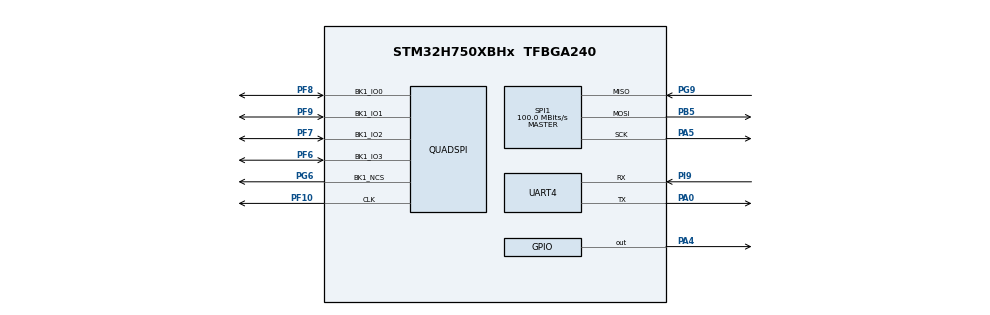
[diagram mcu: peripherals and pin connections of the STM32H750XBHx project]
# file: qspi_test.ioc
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CORTEX_M7.AccessPermission-Cortex_Memory_Protection_Unit_Region0_Settings=MPU_REGION_FULL_ACCESS
CORTEX_M7.BaseAddress-Cortex_Memory_Protection_Unit_Region0_Settings=0x38000000
CORTEX_M7.CPU_DCache=Enabled
CORTEX_M7.CPU_ICache=Enabled
CORTEX_M7.Enable-Cortex_Memory_Protection_Unit_Region0_Settings=MPU_REGION_ENABLE
CORTEX_M7.IsShareable-Cortex_Memory_Protection_Unit_Region0_Settings=MPU_ACCESS_SHAREABLE
CORTEX_M7.MPU_Control=MPU_PRIVILEGED_DEFAULT
CORTEX_M7.Size-Cortex_Memory_Protection_Unit_Region0_Settings=MPU_REGION_SIZE_64KB
CORTEX_M7.default_mode_Activation=0
Dma.Request0=UART4_RX
Dma.UART4_RX.0.Direction=DMA_PERIPH_TO_MEMORY
Dma.UART4_RX.0.EventEnable=DISABLE
Dma.UART4_RX.0.FIFOMode=DMA_FIFOMODE_DISABLE
Dma.UART4_RX.0.Instance=DMA1_Stream0
Dma.UART4_RX.0.MemDataAlignment=DMA_MDATAALIGN_BYTE
Dma.UART4_RX.0.MemInc=DMA_MINC_ENABLE
Dma.UART4_RX.0.Mode=DMA_CIRCULAR
Dma.UART4_RX.0.PeriphDataAlignment=DMA_PDATAALIGN_BYTE
Dma.UART4_RX.0.PeriphInc=DMA_PINC_DISABLE
Dma.UART4_RX.0.Polarity=HAL_DMAMUX_REQ_GEN_RISING
Dma.UART4_RX.0.Priority=DMA_PRIORITY_LOW
Dma.UART4_RX.0.RequestNumber=1
Dma.UART4_RX.0.SignalID=NONE
Dma.UART4_RX.0.SyncEnable=DISABLE
Dma.UART4_RX.0.SyncPolarity=HAL_DMAMUX_SYNC_NO_EVENT
Dma.UART4_RX.0.SyncRequestNumber=1
Dma.UART4_RX.0.SyncSignalID=NONE
Mcu.Family=STM32H7
Mcu.Name=STM32H750XBHx
Mcu.Package=TFBGA240
NVIC.DMA1_Stream0_IRQn=true\:0\:0\:false\:false\:true\:false\:true\:true
NVIC.PriorityGroup=NVIC_PRIORITYGROUP_4
NVIC.QUADSPI_IRQn=true\:0\:0\:false\:false\:true\:true\:true\:true
PA0.Mode=Asynchronous
PA0.Signal=UART4_TX
PA4.GPIO_Speed=GPIO_SPEED_FREQ_VERY_HIGH
PA4.PinState=GPIO_PIN_SET
PA4.Signal=GPIO_Output
PA5.GPIO_Speed=GPIO_SPEED_FREQ_VERY_HIGH
PA5.Mode=Full_Duplex_Master
PA5.Signal=SPI1_SCK
PB5.GPIO_Speed=GPIO_SPEED_FREQ_VERY_HIGH
PB5.Mode=Full_Duplex_Master
PB5.Signal=SPI1_MOSI
PF10.GPIO_Speed=GPIO_SPEED_FREQ_VERY_HIGH
PF10.Mode=Single Bank 1
PF10.Signal=QUADSPI_CLK
PF6.GPIO_Speed=GPIO_SPEED_FREQ_VERY_HIGH
PF6.Mode=Single Bank 1
PF6.Signal=QUADSPI_BK1_IO3
PF7.GPIO_Speed=GPIO_SPEED_FREQ_VERY_HIGH
PF7.Mode=Single Bank 1
PF7.Signal=QUADSPI_BK1_IO2
PF8.GPIO_Speed=GPIO_SPEED_FREQ_VERY_HIGH
PF8.Mode=Single Bank 1
PF8.Signal=QUADSPI_BK1_IO0
PF9.GPIO_Speed=GPIO_SPEED_FREQ_VERY_HIGH
PF9.Mode=Single Bank 1
PF9.Signal=QUADSPI_BK1_IO1
PG6.GPIO_Speed=GPIO_SPEED_FREQ_VERY_HIGH
PG6.Mode=Single Bank 1
PG6.Signal=QUADSPI_BK1_NCS
PG9.GPIO_Speed=GPIO_SPEED_FREQ_VERY_HIGH
PG9.Mode=Full_Duplex_Master
PG9.Signal=SPI1_MISO
PH0-OSC_IN\ (PH0).Mode=HSE-External-Oscillator
PH0-OSC_IN\ (PH0).Signal=RCC_OSC_IN
PH1-OSC_OUT\ (PH1).Mode=HSE-External-Oscillator
PH1-OSC_OUT\ (PH1).Signal=RCC_OSC_OUT
PI9.Mode=Asynchronous
PI9.Signal=UART4_RX
ProjectManager.HeapSize=0x200
ProjectManager.StackSize=0x400
ProjectManager.TargetToolchain=STM32CubeIDE
QUADSPI.ChipSelectHighTime=QSPI_CS_HIGH_TIME_6_CYCLE
QUADSPI.ClockPrescaler=2 - 1
QUADSPI.FifoThreshold=4
QUADSPI.FlashSize=24 - 1
QUADSPI.SampleShifting=QSPI_SAMPLE_SHIFTING_NONE
RCC.ADCFreq_Value=200000000
RCC.APB1Freq_Value=100000000
RCC.APB2Freq_Value=100000000
RCC.APB3Freq_Value=100000000
RCC.APB4Freq_Value=100000000
RCC.CortexFreq_Value=400000000
RCC.D1PPRE=RCC_APB3_DIV2
RCC.D2PPRE1=RCC_APB1_DIV2
RCC.D2PPRE2=RCC_APB2_DIV2
RCC.D3PPRE=RCC_APB4_DIV2
RCC.DIVM1=2
RCC.DIVM2=2
RCC.DIVN1=64
RCC.DIVN2=64
RCC.DIVP2=4
RCC.HCLKFreq_Value=200000000
RCC.HPRE=RCC_HCLK_DIV2
RCC.PLLSourceVirtual=RCC_PLLSOURCE_HSE
RCC.SPI123CLockSelection=RCC_SPI123CLKSOURCE_PLL2
RCC.SYSCLKFreq_VALUE=400000000
RCC.SYSCLKSource=RCC_SYSCLKSOURCE_PLLCLK
RCC.USBFreq_Value=400000000
SPI1.BaudRatePrescaler=SPI_BAUDRATEPRESCALER_2
SPI1.CalculateBaudRate=100.0 MBits/s
SPI1.DataSize=SPI_DATASIZE_8BIT
SPI1.Direction=SPI_DIRECTION_2LINES
SPI1.Mode=SPI_MODE_MASTER
SPI1.VirtualType=VM_MASTER
board=custom

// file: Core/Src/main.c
/* USER CODE BEGIN Header */
/**
  ******************************************************************************
  * @file           : main.c
  * @brief          : Main program body
  ******************************************************************************
  * @attention
  *
  * Copyright (c) 2023 STMicroelectronics.
  * All rights reserved.
  *
  * This software is licensed under terms that can be found in the LICENSE file
  * in the root directory of this software component.
  * If no LICENSE file comes with this software, it is provided AS-IS.
  *
  ******************************************************************************
  */
/* USER CODE END Header */
#include "main.h"
#include "dma.h"
#include "quadspi.h"
#include "spi.h"
#include "usart.h"
#include "gpio.h"

/* USER CODE BEGIN Includes */
#include "qspi_test.h"
/* USER CODE END Includes */

void SystemClock_Config(void);
static void MPU_Config(void);

/* USER CODE BEGIN 0 */

extern DMA_HandleTypeDef hdma_uart4_rx;

static uint8_t spi_id = 0x9F;
static uint8_t spi_id_ret[3] = {0, };

QSPI_CommandTypeDef      s_command;
QSPI_CommandTypeDef      erase_chip;

static __attribute__((section(".none_cache"))) uint8_t uart_rx[100] = {0, };

/* USER CODE END 0 */

int main(void)
{

  /* MPU Configuration--------------------------------------------------------*/
  MPU_Config();

  /* Enable I-Cache---------------------------------------------------------*/
  SCB_EnableICache();

  /* Enable D-Cache---------------------------------------------------------*/
  SCB_EnableDCache();

  /* MCU Configuration--------------------------------------------------------*/

  /* Reset of all peripherals, Initializes the Flash interface and the Systick. */
  HAL_Init();

  /* Configure the system clock */
  SystemClock_Config();

  /* Initialize all configured peripherals */
  MX_GPIO_Init();
  MX_DMA_Init();
  MX_SPI1_Init();
  MX_UART4_Init();
  MX_QUADSPI_Init();
  /* USER CODE BEGIN 2 */
  // mpu region
  HAL_GPIO_WritePin(GPIOA, GPIO_PIN_4, GPIO_PIN_RESET);
  HAL_SPI_Transmit(&hspi1, &spi_id, 1, 0xFF);
  HAL_SPI_Receive(&hspi1, spi_id_ret, 3, 0xFF);
  HAL_GPIO_WritePin(GPIOA, GPIO_PIN_4, GPIO_PIN_SET);

  HAL_UART_Receive_DMA(&huart4, uart_rx, 100);

  qspiTestStart();
  /* USER CODE END 2 */

  /* Infinite loop */
  while (1)
  {

  }
}

void SystemClock_Config(void)
{
  RCC_OscInitTypeDef RCC_OscInitStruct = {0};
  RCC_ClkInitTypeDef RCC_ClkInitStruct = {0};

  /** Supply configuration update enable
  */
  HAL_PWREx_ConfigSupply(PWR_LDO_SUPPLY);

  /** Configure the main internal regulator output voltage
  */
  __HAL_PWR_VOLTAGESCALING_CONFIG(PWR_REGULATOR_VOLTAGE_SCALE1);

  while(!__HAL_PWR_GET_FLAG(PWR_FLAG_VOSRDY)) {}

  /** Macro to configure the PLL clock source
  */
  __HAL_RCC_PLL_PLLSOURCE_CONFIG(RCC_PLLSOURCE_HSE);

  /** Initializes the RCC Oscillators according to the specified parameters
  * in the RCC_OscInitTypeDef structure.
  */
  RCC_OscInitStruct.OscillatorType = RCC_OSCILLATORTYPE_HSE;
  RCC_OscInitStruct.HSEState = RCC_HSE_ON;
  RCC_OscInitStruct.PLL.PLLState = RCC_PLL_ON;
  RCC_OscInitStruct.PLL.PLLSource = RCC_PLLSOURCE_HSE;
  RCC_OscInitStruct.PLL.PLLM = 2;
  RCC_OscInitStruct.PLL.PLLN = 64;
  RCC_OscInitStruct.PLL.PLLP = 2;
  RCC_OscInitStruct.PLL.PLLQ = 2;
  RCC_OscInitStruct.PLL.PLLR = 2;
  RCC_OscInitStruct.PLL.PLLRGE = RCC_PLL1VCIRANGE_3;
  RCC_OscInitStruct.PLL.PLLVCOSEL = RCC_PLL1VCOWIDE;
  RCC_OscInitStruct.PLL.PLLFRACN = 0;
  if (HAL_RCC_OscConfig(&RCC_OscInitStruct) != HAL_OK)
  {
    Error_Handler();
  }

  /** Initializes the CPU, AHB and APB buses clocks
  */
  RCC_ClkInitStruct.ClockType = RCC_CLOCKTYPE_HCLK|RCC_CLOCKTYPE_SYSCLK
                              |RCC_CLOCKTYPE_PCLK1|RCC_CLOCKTYPE_PCLK2
                              |RCC_CLOCKTYPE_D3PCLK1|RCC_CLOCKTYPE_D1PCLK1;
  RCC_ClkInitStruct.SYSCLKSource = RCC_SYSCLKSOURCE_PLLCLK;
  RCC_ClkInitStruct.SYSCLKDivider = RCC_SYSCLK_DIV1;
  RCC_ClkInitStruct.AHBCLKDivider = RCC_HCLK_DIV2;
  RCC_ClkInitStruct.APB3CLKDivider = RCC_APB3_DIV2;
  RCC_ClkInitStruct.APB1CLKDivider = RCC_APB1_DIV2;
  RCC_ClkInitStruct.APB2CLKDivider = RCC_APB2_DIV2;
  RCC_ClkInitStruct.APB4CLKDivider = RCC_APB4_DIV2;

  if (HAL_RCC_ClockConfig(&RCC_ClkInitStruct, FLASH_LATENCY_2) != HAL_OK)
  {
    Error_Handler();
  }
}

/* MPU Configuration */

void MPU_Config(void)
{
  MPU_Region_InitTypeDef MPU_InitStruct = {0};

  /* Disables the MPU */
  HAL_MPU_Disable();

  /** Initializes and configures the Region and the memory to be protected
  */
  MPU_InitStruct.Enable = MPU_REGION_ENABLE;
  MPU_InitStruct.Number = MPU_REGION_NUMBER0;
  MPU_InitStruct.BaseAddress = 0x38000000;
  MPU_InitStruct.Size = MPU_REGION_SIZE_64KB;
  MPU_InitStruct.SubRegionDisable = 0x0;
  MPU_InitStruct.TypeExtField = MPU_TEX_LEVEL0;
  MPU_InitStruct.AccessPermission = MPU_REGION_FULL_ACCESS;
  MPU_InitStruct.DisableExec = MPU_INSTRUCTION_ACCESS_ENABLE;
  MPU_InitStruct.IsShareable = MPU_ACCESS_SHAREABLE;
  MPU_InitStruct.IsCacheable = MPU_ACCESS_NOT_CACHEABLE;
  MPU_InitStruct.IsBufferable = MPU_ACCESS_NOT_BUFFERABLE;

  HAL_MPU_ConfigRegion(&MPU_InitStruct);
  /* Enables the MPU */
  HAL_MPU_Enable(MPU_PRIVILEGED_DEFAULT);

}

void Error_Handler(void)
{
  __disable_irq();
  while (1)
  {
  }
}
